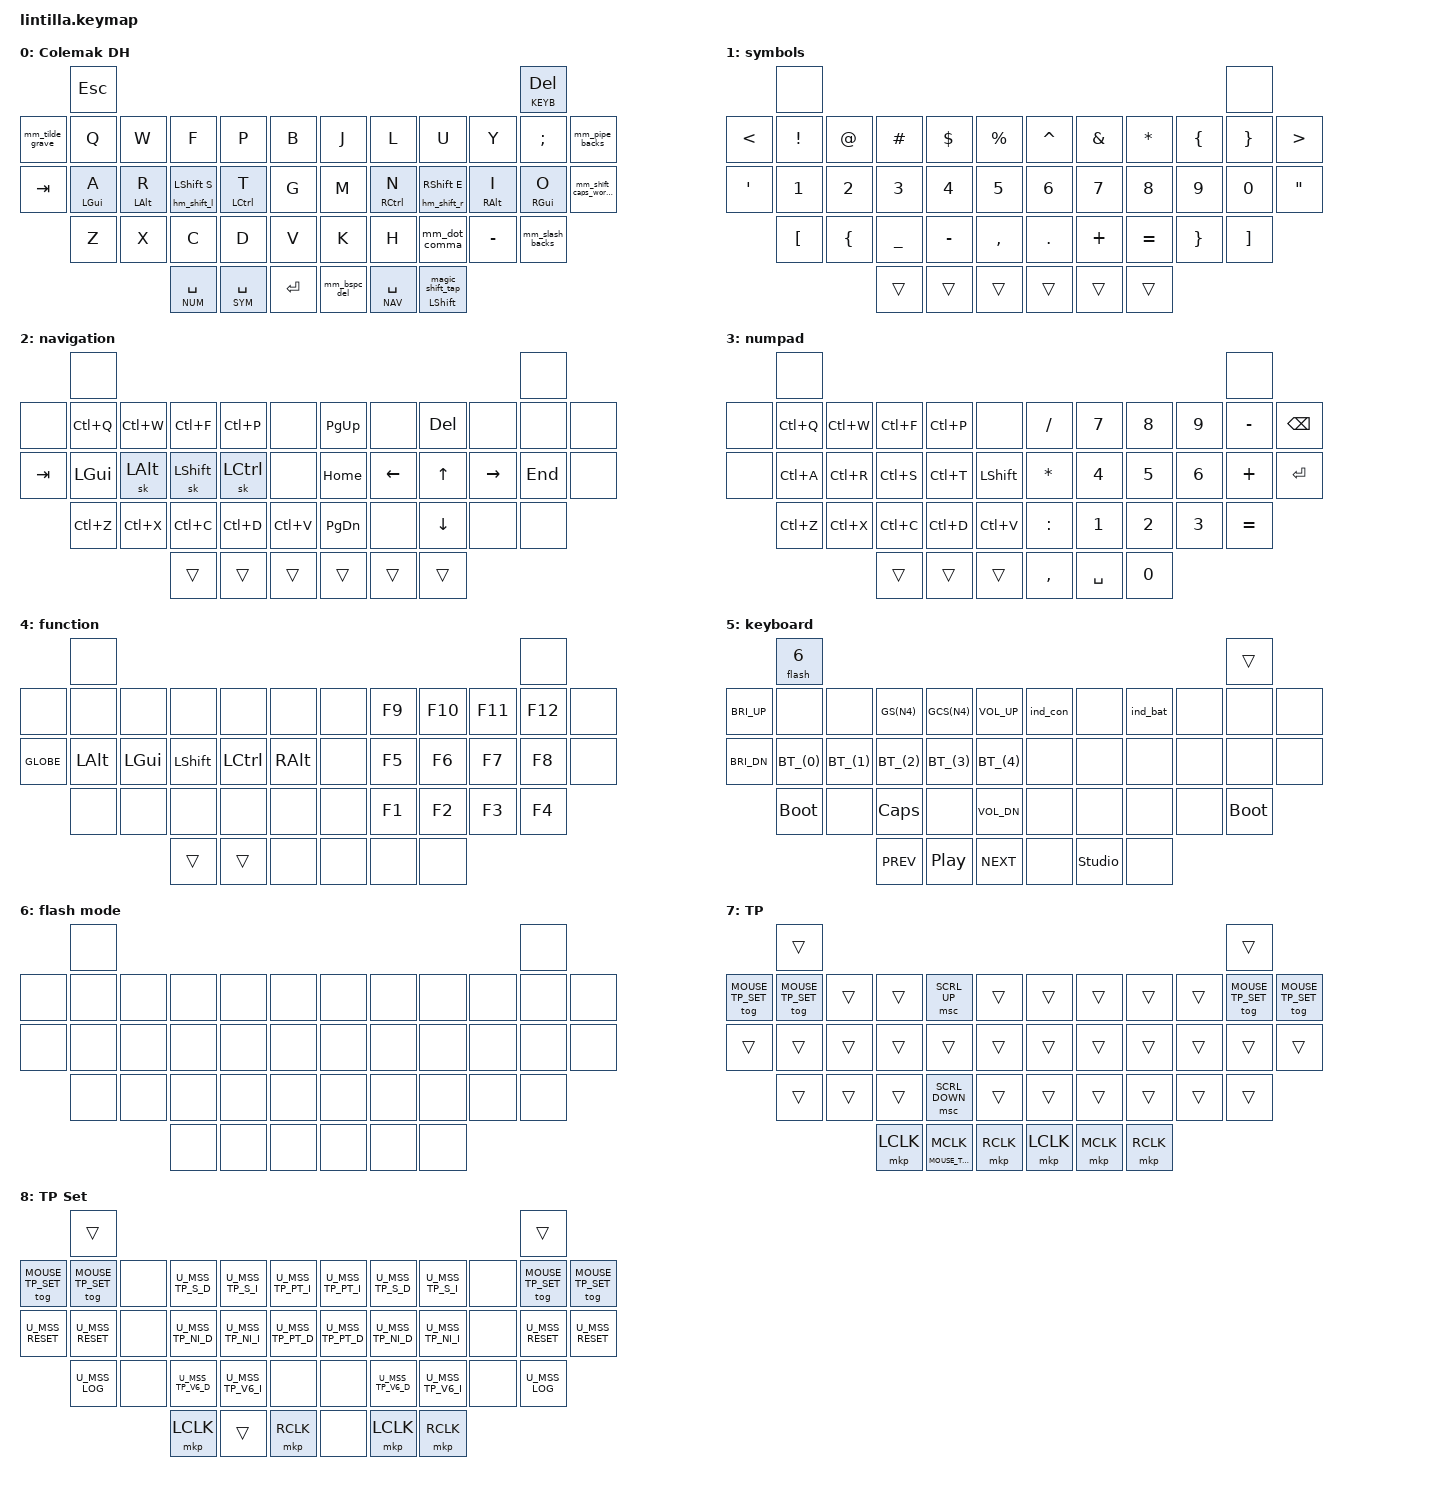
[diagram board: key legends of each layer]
#include "includes/lintilla.h"

#define KEYS_L LN0 LT0 LT1 LT2 LT3 LT4 LT5 LM0 LM1 LM2 LM3 LM4 LM5 LB0 LB1 LB2 LB3 LB4
#define KEYS_R RN0 RT0 RT1 RT2 RT3 RT4 RT5 RM0 RM1 RM2 RM3 RM4 RM5 RB0 RB1 RB2 RB3 RB4
#define KEYS_T LH2 LH1 LH0 RH0 RH1 RH2

#include <behaviors.dtsi>
#include <dt-bindings/zmk/bt.h>
#include <dt-bindings/zmk/keys.h>
#include <dt-bindings/zmk/outputs.h>
#include <dt-bindings/zmk/pointing.h>
#include <behaviors/rgbled_widget.dtsi>

// Personal includes
#define HOST_OS 1
#include "zmk-helpers/helper.h"

// Set the scroll amount
#undef ZMK_MOUSE_DEFAULT_SCRL_VAL
#define ZMK_MOUSE_DEFAULT_SCRL_VAL 1000

#undef SCRL_UP
#undef SCRL_DOWN
#undef SCRL_LEFT
#undef SCRL_RIGHT
#define SCRL_UP MOVE_Y(ZMK_MOUSE_DEFAULT_SCRL_VAL)
#define SCRL_DOWN MOVE_Y(-ZMK_MOUSE_DEFAULT_SCRL_VAL)
#define SCRL_LEFT MOVE_X(-ZMK_MOUSE_DEFAULT_SCRL_VAL)
#define SCRL_RIGHT MOVE_X(ZMK_MOUSE_DEFAULT_SCRL_VAL)
#define HAS_MOUSE_TP

// Source unicode-chars for desired languages
#include "zmk-helpers/unicode-chars/german.dtsi"
#include "includes/settings.dtsi"
#include "includes/behaviors_homerow_mods.dtsi"
#include "includes/behaviors_mod_morph.dtsi"
#include "includes/behaviors_other.dtsi"
#ifdef HAS_MOUSE_TP
  // We store the trackpoint settings in a separate file
  // to make organization a little easier.
  #include "includes/mouse_tp.dtsi"
#endif  // HAS_MOUSE_TP
#ifdef HAS_MOUSE_TP
  #define U_TOG_TP_SET &tog MOUSE_TP_SET
#else
  #define U_TOG_TP_SET &none
#endif  // HAS_MOUSE_TP

// Multiple mods
#define GS(key) &kp LG(LS(key))
#define GCS(key) &kp LG(LC(LS(key)))
#define HYPR(key) &kp LG(LA(LC(LS(key))))

// Shortcuts for home row mods
#define Glb &hm GLOBE
#define Sft &hm LSHFT
#define Ctl &hm LCTRL
#define Opt &hm LALT
#define Cmd &hm LGUI
#define Alt &hm RALT

// Magic bluetooth button
#define BT_(btnum) &bt_key btnum btnum

#define QUICK_TAP_MS 175

// Tap: repeat after alpha, else sticky-shift |
// Shift + tap/ double-tap: caps-word | Hold: shift.
#define MAGIC_SHIFT &magic_shift LSHFT 0
ZMK_HOLD_TAP(magic_shift, bindings = <&kp>, <&magic_shift_tap>;
             flavor = "balanced"; tapping-term-ms = <200>;
             quick-tap-ms = <QUICK_TAP_MS>;)
ZMK_MOD_MORPH(magic_shift_tap, bindings = <&sk LSHFT>, <&caps_word>;
              mods = <(MOD_LSFT)>;)

//&msc {
//    time-to-max-speed-ms = <1000>;
//};

/ {
    behaviors {
        bt_key: magic_bluetooth_key {
            compatible = "zmk,behavior-hold-tap";
            #binding-cells = <2>;
            flavor = "tap-preferred";
            tapping-term-ms = <500>;
            bindings = <&bt_clr>, <&bt_sel>;
        };

        hrm: homerow_mod {
            compatible = "zmk,behavior-hold-tap";
            #binding-cells = <2>;
            tapping-term-ms = <300>;
            require-prior-idle-ms = <150>;
            quick-tap-ms = <0>;
            flavor = "tap-preferred";
            bindings = <&kp>, <&kp>;
        };

        // Setting behavior for scrolling
        mouse_wheel: mouse_wheel {
            compatible = "zmk,behavior-sensor-rotate-var";
            label = "MOUSE_WHEEL";
            #sensor-binding-cells = <2>;
            bindings = <&msc>, <&msc>;
            tap-ms = <20>;
            };
    };

    conditional_layers {
        compatible = "zmk,conditional-layers";
        function_layer {
            if-layers = <NUM SYM>;
            then-layer = <FUNC>;
        };
    };

    macros {
        bt_clr: bluetooth_clear {
            compatible = "zmk,behavior-macro-one-param";
            #binding-cells = <1>;
            bindings = <&macro_param_1to1 &bt_sel MACRO_PLACEHOLDER>, <&bt BT_CLR>;
        };

        bt_sel: bluetooth_select {
            compatible = "zmk,behavior-macro-one-param";
            #binding-cells = <1>;
            bindings = <&out OUT_BLE>, <&macro_param_1to2 &bt BT_SEL MACRO_PLACEHOLDER>;
        };

        flash: dongle_bootloader {
            compatible = "zmk,behavior-macro-one-param";
            #binding-cells = <1>;
            bindings = <&macro_param_1to1 &to MACRO_PLACEHOLDER>, <&bootloader>;
        };
    };

    keymap {
        compatible = "zmk,keymap";

        colemak {
//                       ┏━━━━━━━━━━━━━━━━━━━━━━━━━┓
            display-name = "Colemak DH"                ;
//                       ┗━━━━━━━━━━━━━━━━━━━━━━━━━┛
            bindings = <
//                          ╭────────────────────────╮                                                                                                                                                                                                           ╭────────────────────────╮
                              &kp ESC                                                                                                                                                                                                                              &lt KEYB DEL                                                
// ╭────────────────────────┼────────────────────────┼────────────────────────┬────────────────────────┬────────────────────────┬────────────────────────╮    ╭────────────────────────┬────────────────────────┬────────────────────────┬───────────────────────┼────────────────────────┼────────────────────────╮
     &mm_tilde_grave          &kp Q                    &kp W                    &kp F                    &kp P                    &kp B                         &kp J                    &kp L                    &kp U                    &kp Y                   &kp SEMICOLON            &mm_pipe_backs
// ├────────────────────────┼────────────────────────┼────────────────────────┼────────────────────────┼────────────────────────┼────────────────────────┤    ├────────────────────────┼────────────────────────┼────────────────────────┼───────────────────────┼────────────────────────┼────────────────────────┤
     &kp TAB                  &hm_l LGUI A             &hm_l LALT R             &hm_shift_l LSHFT S      &hm_l LCTRL T            &kp G                         &kp M                    &hm_r RCTRL N            &hm_shift_r RSHFT E      &hm_r RALT I            &hm_r RGUI O             &mm_shift_caps_word_r
// ╰────────────────────────┼────────────────────────┼────────────────────────┼────────────────────────┼────────────────────────┼────────────────────────┤    ├────────────────────────┼────────────────────────┼────────────────────────┼───────────────────────┼────────────────────────┼────────────────────────╯
                              &kp Z                    &kp X                    &kp C                    &kp D                    &kp V                         &kp K                    &kp H                    &mm_dot_comma            &kp MINUS                &mm_slash_backs              
//                          ╰────────────────────────┴────────────────────────┴────────────────────────┼────────────────────────┼────────────────────────┤    ├────────────────────────┼────────────────────────┼────────────────────────┼───────────────────────┴────────────────────────╯
                                                                                &lt NUM SPACE           &lt SYM SPACE            &kp RETURN                     &mm_bspc_del             &lt NAV SPACE            MAGIC_SHIFT
//                                                                            ╰────────────────────────┴────────────────────────┴────────────────────────╯    ╰────────────────────────┴────────────────────────┴────────────────────────╯
      >;
    sensor-bindings = <&mouse_wheel SCRL_UP SCRL_DOWN>;
    };

//    Base_Qwerty_layer {
//      display-name = "QWERTY";
//      bindings = <
////                          ╭────────────────────────╮                                                                                                                                                                                                           ╭────────────────────────╮
//                              &trans                                                                                                                                                                                                                                &trans                                                
//// ╭────────────────────────┼────────────────────────┼────────────────────────┬────────────────────────┬────────────────────────┬────────────────────────╮    ╭────────────────────────┬────────────────────────┬────────────────────────┬───────────────────────┼────────────────────────┼────────────────────────╮
//     &trans                   &trans                   &trans                   &kp E                    &kp R                    &kp T                         &kp Y                    &kp U                    &kp I                    &kp O                    &kp P                     &trans
//// ├────────────────────────┼────────────────────────┼────────────────────────┼────────────────────────┼────────────────────────┼────────────────────────┤    ├────────────────────────┼────────────────────────┼────────────────────────┼───────────────────────┼────────────────────────┼────────────────────────┤
//     &trans                   &kp A                    &kp S                    &kp D                    &kp F                    &trans                        &kp H                    &kp J                    &kp K                    &kp L                    &kp SEMICOLON             &trans
//// ╰────────────────────────┼────────────────────────┼────────────────────────┼────────────────────────┼────────────────────────┼────────────────────────┤    ├────────────────────────┼────────────────────────┼────────────────────────┼───────────────────────┼────────────────────────┼────────────────────────╯
//                              &trans                   &trans                   &kp C                    &kp V                    &kp B                         &kp N                    &kp M                    &kp COMMA                &trans                   &trans                 
////                          ╰────────────────────────┴────────────────────────┴────────────────────────┼────────────────────────┼────────────────────────┤    ├────────────────────────┼────────────────────────┼────────────────────────┼───────────────────────┴────────────────────────╯
//                                                                                &trans                   &trans                   &trans                        &trans                   &trans                   &trans
////                                                                            ╰────────────────────────┴────────────────────────┴────────────────────────╯    ╰────────────────────────┴────────────────────────┴────────────────────────╯
//      >;
//    };

        sym {
//                       ┏━━━━━━━━━━━━━━━━━━━━━━━━━┓
            display-name = "symbols"               ;
//                       ┗━━━━━━━━━━━━━━━━━━━━━━━━━┛
            bindings = <
//         ┏━━━━━━━┓                                                                                          ┏━━━━━━━┓
//         ┃       ┃                                                                                          ┃       ┃
             &none                                                                                              &none
// ┏━━━━━━━╋━━━━━━━╋━━━━━━━┳━━━━━━━┳━━━━━━━┳━━━━━━━┓                          ┏━━━━━━━┳━━━━━━━┳━━━━━━━┳━━━━━━━╋━━━━━━━╋━━━━━━━┓
// ┃   <   ┃   !   ┃   @   ┃   #   ┃   $   ┃   %   ┃                          ┃    ^  ┃   &   ┃   *   ┃  (    ┃   )   ┃   >   ┃
    &kp LT &kp EXCL &kp AT  &kp HASH &kp DLLR &kp PRCNT                        &kp CARET &kp AMPS &kp STAR &kp LEFT_BRACE &kp RIGHT_BRACE &kp GT
// ┣━━━━━━━╋━━━━━━━╋━━━━━━━╋━━━━━━━╋━━━━━━━╋━━━━━━━┫                          ┣━━━━━━━╋━━━━━━━╋━━━━━━━╋━━━━━━━╋━━━━━━━╋━━━━━━━┫
// ┃   '   ┃   1   ┃   2   ┃   3   ┃   4   ┃   5   ┃                          ┃   6   ┃   7   ┃   8   ┃   9   ┃   0   ┃   "   ┃
    &kp SINGLE_QUOTE  &kp N1  &kp N2  &kp N3  &kp N4  &kp N5                   &kp N6  &kp N7  &kp N8  &kp N9  &kp N0  &kp DOUBLE_QUOTES
// ┗━━━━━━━╋━━━━━━━╋━━━━━━━╋━━━━━━━╋━━━━━━━╋━━━━━━━┫                          ┣━━━━━━━╋━━━━━━━╋━━━━━━━╋━━━━━━━╋━━━━━━━╋━━━━━━━┛
//         ┃   [   ┃   {   ┃   _   ┃   -   ┃   ,   ┃                          ┃   .   ┃   +   ┃   =   ┃   }   ┃   ]   ┃
            &kp LBKT &kp LBRC &kp UNDER &kp MINUS &kp COMMA                    &kp DOT &kp PLUS &kp EQUAL &kp RBRC &kp RBKT
//         ┗━━━━━━━┻━━━━━━━┻━━━━━━━┻━━━┳━━━┻━━━┳━━━┻━━━┳━━━━━━━┓  ┏━━━━━━━┳━━━┻━━━┳━━━┻━━━┳━━━┻━━━━━━━┻━━━━━━━┻━━━━━━━┛
//                                     ┃ ##### ┃ ##### ┃ ##### ┃  ┃ ##### ┃ ##### ┃ ##### ┃
                                         &trans  &trans  &trans    &trans  &trans  &trans
//                                     ┗━━━━━━━┫       ┣━━━━━━━┛  ┗━━━━━━━┫       ┣━━━━━━━┛
//                                             ┗━━━━━━━┛                  ┗━━━━━━━┛
            >;
        sensor-bindings = <&inc_dec_kp PLUS MINUS>;

        };

        nav {
//                       ┏━━━━━━━━━━━━━━━━━━━━━━━━━┓
            display-name = "navigation"            ;
//                       ┗━━━━━━━━━━━━━━━━━━━━━━━━━┛
            bindings = <
//         ┏━━━━━━━┓                                                                                          ┏━━━━━━━┓
//         ┃       ┃                                                                                          ┃       ┃
             &none                                                                                              &none
// ┏━━━━━━━╋━━━━━━━╋━━━━━━━┳━━━━━━━┳━━━━━━━┳━━━━━━━┓                          ┏━━━━━━━┳━━━━━━━┳━━━━━━━┳━━━━━━━╋━━━━━━━╋━━━━━━━┓
// ┃       ┃       ┃       ┃       ┃       ┃       ┃                          ┃ Pg Up ┃       ┃  DEL  ┃       ┃       ┃       ┃
&none &kp LC(Q) &kp LC(W) &kp LC(F) &kp LC(P) &none                           &kp PG_UP &none   &kp DEL &none   &none   &none
// ┣━━━━━━━╋━━━━━━━╋━━━━━━━╋━━━━━━━╋━━━━━━━╋━━━━━━━┫                          ┣━━━━━━━╋━━━━━━━╋━━━━━━━╋━━━━━━━╋━━━━━━━╋━━━━━━━┫
// ┃       ┃ LGUI  ┃  LALT ┃ LSHFT ┃ LCTRL ┃ none  ┃                          ┃ Home  ┃ Left  ┃  Up   ┃ Right ┃  End  ┃       ┃
&kp TAB &kp LGUI &sk LALT &sk LSHFT &sk LCTRL &none                           &kp HOME &kp LEFT &kp UP &kp RIGHT &kp END &none
// ┃       ┃       ┃       ┃       ┃       ┃       ┃                          ┃       ┃       ┃       ┃       ┃       ┃       ┃
// ┗━━━━━━━╋━━━━━━━╋━━━━━━━╋━━━━━━━╋━━━━━━━╋━━━━━━━┫                          ┣━━━━━━━╋━━━━━━━╋━━━━━━━╋━━━━━━━╋━━━━━━━╋━━━━━━━┛
//         ┃ CtrlZ ┃ CtrlX ┃ CtrlC ┃ CtrlD ┃ CtrlV ┃                          ┃ Pg Dn ┃       ┃ Down  ┃       ┃       ┃
         &kp LC(Z) &kp LC(X) &kp LC(C) &kp LC(D) &kp LC(V)                    &kp PG_DN &none  &kp DOWN &none   &none
//         ┗━━━━━━━┻━━━━━━━┻━━━━━━━┻━━━┳━━━┻━━━┳━━━┻━━━┳━━━━━━━┓  ┏━━━━━━━┳━━━┻━━━┳━━━┻━━━┳━━━┻━━━━━━━┻━━━━━━━┻━━━━━━━┛
//                                     ┃ ##### ┃ ##### ┃ ##### ┃  ┃ ##### ┃ ##### ┃ ##### ┃
                                         &trans  &trans  &trans     &trans  &trans  &trans
//                                     ┗━━━━━━━┫       ┣━━━━━━━┛  ┗━━━━━━━┫       ┣━━━━━━━┛
//                                             ┗━━━━━━━┛                  ┗━━━━━━━┛
            >;
     //sensor-bindings = <&mouse_wheel SCROLL_RIGHT SCROLL_LEFT>;
    sensor-bindings = <&inc_dec_kp C_VOL_UP C_VOL_DN>;
        };

        num {
//                       ┏━━━━━━━━━━━━━━━━━━━━━━━━━┓
            display-name = "numpad"                ;
//                       ┗━━━━━━━━━━━━━━━━━━━━━━━━━┛
            bindings = <
//         ┏━━━━━━━┓                                                                                          ┏━━━━━━━┓
//         ┃       ┃                                                                                          ┃       ┃
             &none                                                                                              &none
// ┏━━━━━━━╋━━━━━━━╋━━━━━━━┳━━━━━━━┳━━━━━━━┳━━━━━━━┓                          ┏━━━━━━━┳━━━━━━━┳━━━━━━━┳━━━━━━━╋━━━━━━━╋━━━━━━━┓
// ┃       ┃       ┃       ┃       ┃       ┃       ┃                          ┃   /   ┃   7   ┃   8   ┃   9   ┃   -   ┃ BKSPC ┃
&none &kp LC(Q) &kp LC(W) &kp LC(F) &kp LC(P) &none                           &kp SLASH &kp N7 &kp N8  &kp N9 &kp MINUS &kp BSPC
// ┣━━━━━━━╋━━━━━━━╋━━━━━━━╋━━━━━━━╋━━━━━━━╋━━━━━━━┫                          ┣━━━━━━━╋━━━━━━━╋━━━━━━━╋━━━━━━━╋━━━━━━━╋━━━━━━━┫
// ┃       ┃ CtrlA ┃ CtrlR ┃ CtrlS ┃ CtrlT ┃ LSHFT ┃                          ┃   *   ┃   4   ┃   5   ┃   6   ┃   +   ┃RETURN ┃
&none &kp LC(A) &kp LC(R) &kp LC(S) &kp LC(T) &kp LSHFT                       &kp STAR &kp N4  &kp N5  &kp N6 &kp PLUS &kp RET
// ┃       ┃       ┃       ┃       ┃       ┃       ┃                          ┃       ┃       ┃       ┃       ┃       ┃       ┃
// ┗━━━━━━━╋━━━━━━━╋━━━━━━━╋━━━━━━━╋━━━━━━━╋━━━━━━━┫                          ┣━━━━━━━╋━━━━━━━╋━━━━━━━╋━━━━━━━╋━━━━━━━╋━━━━━━━┛
//         ┃ CtrlZ ┃ CtrlX ┃ CtrlC ┃ CtrlD ┃ CtrlV ┃                          ┃   :   ┃   1   ┃   2   ┃   3   ┃   =   ┃
         &kp LC(Z) &kp LC(X) &kp LC(C) &kp LC(D) &kp LC(V)                    &kp COLON &kp N1 &kp N2  &kp N3 &kp EQUAL
//         ┗━━━━━━━┻━━━━━━━┻━━━━━━━┻━━━┳━━━┻━━━┳━━━┻━━━┳━━━━━━━┓  ┏━━━━━━━┳━━━┻━━━┳━━━┻━━━┳━━━┻━━━━━━━┻━━━━━━━┻━━━━━━━┛
//                                     ┃ ##### ┃ ##### ┃ ##### ┃  ┃   .   ┃ SPACE ┃   0   ┃
                                         &trans  &trans  &trans    &kp COMMA &kp SPC &kp N0
//                                     ┗━━━━━━━┫       ┣━━━━━━━┛  ┗━━━━━━━┫       ┣━━━━━━━┛
//                                             ┗━━━━━━━┛                  ┗━━━━━━━┛
            >;
        };

        fn {
//                       ┏━━━━━━━━━━━━━━━━━━━━━━━━━┓
            display-name = "function"              ;
//                       ┗━━━━━━━━━━━━━━━━━━━━━━━━━┛
            bindings = <
//         ┏━━━━━━━┓                                                                                          ┏━━━━━━━┓
//         ┃       ┃                                                                                          ┃       ┃
             &none                                                                                              &none
// ┏━━━━━━━╋━━━━━━━╋━━━━━━━┳━━━━━━━┳━━━━━━━┳━━━━━━━┓                          ┏━━━━━━━┳━━━━━━━┳━━━━━━━┳━━━━━━━╋━━━━━━━╋━━━━━━━┓
// ┃       ┃       ┃       ┃       ┃       ┃       ┃                          ┃       ┃  F9   ┃  F10  ┃  F11  ┃  F12  ┃       ┃
     &none   &none   &none   &none   &none   &none                              &none  &kp F9  &kp F10 &kp F11 &kp F12  &none
// ┣━━━━━━━╋━━━━━━━╋━━━━━━━╋━━━━━━━╋━━━━━━━╋━━━━━━━┫                          ┣━━━━━━━╋━━━━━━━╋━━━━━━━╋━━━━━━━╋━━━━━━━╋━━━━━━━┫
// ┃ Globe ┃ L Alt ┃  GUI  ┃ Shift ┃  Ctrl ┃ R Alt ┃                          ┃       ┃  F5   ┃  F6   ┃  F7   ┃  F8   ┃       ┃
&kp GLOBE  &kp LALT  &kp LGUI  &kp LSHFT &kp LCTL &kp RALT                      &none  &kp F5  &kp F6  &kp F7  &kp F8   &none
// ┗━━━━━━━╋━━━━━━━╋━━━━━━━╋━━━━━━━╋━━━━━━━╋━━━━━━━┫                          ┣━━━━━━━╋━━━━━━━╋━━━━━━━╋━━━━━━━╋━━━━━━━╋━━━━━━━┛
//         ┃       ┃       ┃       ┃       ┃       ┃                          ┃       ┃  F1   ┃  F2   ┃  F3   ┃  F4   ┃
             &none   &none   &none   &none   &none                              &none  &kp F1  &kp F2  &kp F3  &kp F4
//         ┗━━━━━━━┻━━━━━━━┻━━━━━━━┻━━━┳━━━┻━━━┳━━━┻━━━┳━━━━━━━┓  ┏━━━━━━━┳━━━┻━━━┳━━━┻━━━┳━━━┻━━━━━━━┻━━━━━━━┻━━━━━━━┛
//                                     ┃ ##### ┃ ##### ┃       ┃  ┃       ┃       ┃       ┃
                                         &trans  &trans  &none      &none   &none   &none
//                                     ┗━━━━━━━┫       ┣━━━━━━━┛  ┗━━━━━━━┫       ┣━━━━━━━┛
//                                             ┗━━━━━━━┛                  ┗━━━━━━━┛
            >;
        };

        keybd {
//                       ┏━━━━━━━━━━━━━━━━━━━━━━━━━┓
            display-name = "keyboard"              ;
//                       ┗━━━━━━━━━━━━━━━━━━━━━━━━━┛
            bindings = <
//         ┏━━━━━━━┓                                                                                          ┏━━━━━━━┓
//         ┃ dongle┃                                                                                          ┃ ##### ┃
           &flash 6                                                                                             &trans
// ┏━━━━━━━╋━━━━━━━╋━━━━━━━┳━━━━━━━┳━━━━━━━┳━━━━━━━┓                          ┏━━━━━━━┳━━━━━━━┳━━━━━━━┳━━━━━━━╋━━━━━━━╋━━━━━━━┓
// ┃ brt + ┃       ┃       ┃scrnsht┃scrn cp┃ vol + ┃                          ┃con led┃       ┃bat led┃       ┃       ┃       ┃
&kp C_BRI_UP &none   &none  GS(N4) GCS(N4) &kp C_VOL_UP                       &ind_con  &none &ind_bat  &none   &none   &none
// ┣━━━━━━━╋━━━━━━━╋━━━━━━━╋━━━━━━━╋━━━━━━━╋━━━━━━━┫                          ┣━━━━━━━╋━━━━━━━╋━━━━━━━╋━━━━━━━╋━━━━━━━╋━━━━━━━┫
// ┃ brt - ┃  BT1  ┃  BT2  ┃  BT3  ┃  BT4  ┃  BT5  ┃                          ┃       ┃       ┃       ┃       ┃       ┃       ┃
&kp C_BRI_DN BT_(0)  BT_(1)  BT_(2)  BT_(3)  BT_(4)                             &none   &none   &none   &none   &none   &none
// ┗━━━━━━━╋━━━━━━━╋━━━━━━━╋━━━━━━━╋━━━━━━━╋━━━━━━━┫                          ┣━━━━━━━╋━━━━━━━╋━━━━━━━╋━━━━━━━╋━━━━━━━╋━━━━━━━┛
//         ┃ flash ┃       ┃caps lk┃       ┃ vol - ┃                          ┃       ┃       ┃       ┃       ┃ flash ┃
        &bootloader &none &kp CAPS &none &kp C_VOL_DN                           &none   &none   &none   &none &bootloader
//         ┗━━━━━━━┻━━━━━━━┻━━━━━━━┻━━━┳━━━┻━━━┳━━━┻━━━┳━━━━━━━┓  ┏━━━━━━━┳━━━┻━━━┳━━━┻━━━┳━━━┻━━━━━━━┻━━━━━━━┻━━━━━━━┛
//                                     ┃ prev  ┃ play  ┃ next  ┃  ┃       ┃studio ┃       ┃
                                   &kp C_PREV &kp C_PP &kp C_NEXT &none &studio_unlock &none
//                                     ┗━━━━━━━┫       ┣━━━━━━━┛  ┗━━━━━━━┫ unlock┣━━━━━━━┛
//                                             ┗━━━━━━━┛                  ┗━━━━━━━┛
            >;
        };

        flash {
//                       ┏━━━━━━━━━━━━━━━━━━━━━━━━━┓
            display-name = "flash mode"            ;
//                       ┗━━━━━━━━━━━━━━━━━━━━━━━━━┛
            bindings = <
//         ┏━━━━━━━┓                                                                                          ┏━━━━━━━┓
//         ┃       ┃                                                                                          ┃       ┃
             &none                                                                                              &none
// ┏━━━━━━━╋━━━━━━━╋━━━━━━━┳━━━━━━━┳━━━━━━━┳━━━━━━━┓                          ┏━━━━━━━┳━━━━━━━┳━━━━━━━┳━━━━━━━╋━━━━━━━╋━━━━━━━┓
// ┃       ┃       ┃       ┃       ┃       ┃       ┃                          ┃       ┃       ┃       ┃       ┃       ┃       ┃
     &none   &none   &none   &none   &none   &none                              &none   &none   &none   &none   &none   &none
// ┣━━━━━━━╋━━━━━━━╋━━━━━━━╋━━━━━━━╋━━━━━━━╋━━━━━━━┫                          ┣━━━━━━━╋━━━━━━━╋━━━━━━━╋━━━━━━━╋━━━━━━━╋━━━━━━━┫
// ┃       ┃       ┃       ┃       ┃       ┃       ┃                          ┃       ┃       ┃       ┃       ┃       ┃       ┃
     &none   &none   &none   &none   &none   &none                              &none   &none   &none   &none   &none   &none
// ┗━━━━━━━╋━━━━━━━╋━━━━━━━╋━━━━━━━╋━━━━━━━╋━━━━━━━┫                          ┣━━━━━━━╋━━━━━━━╋━━━━━━━╋━━━━━━━╋━━━━━━━╋━━━━━━━┛
//         ┃       ┃       ┃       ┃       ┃       ┃                          ┃       ┃       ┃       ┃       ┃       ┃
             &none   &none   &none   &none   &none                              &none   &none   &none   &none   &none
//         ┗━━━━━━━┻━━━━━━━┻━━━━━━━┻━━━┳━━━┻━━━┳━━━┻━━━┳━━━━━━━┓  ┏━━━━━━━┳━━━┻━━━┳━━━┻━━━┳━━━┻━━━━━━━┻━━━━━━━┻━━━━━━━┛
//                                     ┃       ┃       ┃       ┃  ┃       ┃       ┃       ┃
                                         &none   &none   &none      &none   &none   &none
//                                     ┗━━━━━━━┫       ┣━━━━━━━┛  ┗━━━━━━━┫       ┣━━━━━━━┛
//                                             ┗━━━━━━━┛                  ┗━━━━━━━┛
            >;
        };
#ifdef HAS_MOUSE_TP

        // Automatically activated when the mouse or trackpoint moves.
        // Configured in `include/mouse_tp.dtsi`.
        MouseTP_layer {
        display-name = "TP";
        bindings = <

//                              ╭────────────────────────╮                                                                                                                                                                                                            ╭────────────────────────╮
                                 &trans                                                                                                                                                                                                                               &trans                                            
//     ╭────────────────────────┼────────────────────────┼────────────────────────┬────────────────────────┬────────────────────────┬────────────────────────╮    ╭────────────────────────┬────────────────────────┬────────────────────────┬────────────────────────┼────────────────────────┼────────────────────────╮
        U_TOG_TP_SET             U_TOG_TP_SET             &trans                   &trans                   &msc SCRL_UP             &trans                        &trans                   &trans                   &trans                   &trans                   U_TOG_TP_SET              U_TOG_TP_SET
    // ├────────────────────────┼────────────────────────┼────────────────────────┼────────────────────────┼────────────────────────┼────────────────────────┤    ├────────────────────────┼────────────────────────┼────────────────────────┼────────────────────────┼────────────────────────┼────────────────────────┤
        &trans                   &trans                   &trans                   &trans                   &trans                   &trans                        &trans                   &trans                   &trans                   &trans                   &trans                    &trans
    // ╰────────────────────────┼────────────────────────┼────────────────────────┼────────────────────────┼────────────────────────┼────────────────────────┤    ├────────────────────────┼────────────────────────┼────────────────────────┼────────────────────────┼────────────────────────┼────────────────────────╯
                                 &trans                   &trans                   &trans                   &msc SCRL_DOWN           &trans                        &trans                   &trans                   &trans                   &trans                   &trans                  
    //                          ╰────────────────────────┴────────────────────────┴────────────────────────┼────────────────────────┼────────────────────────┤    ├────────────────────────┼────────────────────────┼────────────────────────┼────────────────────────┴────────────────────────╯
                                                                                    &mkp LCLK               &lt_mkp MOUSE_TP_SET MCLK &mkp RCLK                     &mkp LCLK                &mkp MCLK                &mkp RCLK
    //                                                                            ╰────────────────────────┴────────────────────────┴────────────────────────╯    ╰────────────────────────┴────────────────────────┴────────────────────────╯
        >;
        };

        // You can find the defines for the actual key press behaviors in `include/mouse_tp.dtsi`.
        MouseSettings_layer {
        display-name = "TP Set";
        bindings = <
//                              ╭────────────────────────╮                                                                                                                                                                                                            ╭────────────────────────╮
                                 &trans                                                                                                                                                                                                                               &trans                                            
//     ╭────────────────────────┼────────────────────────┼────────────────────────┬────────────────────────┬────────────────────────┬────────────────────────╮    ╭────────────────────────┬────────────────────────┬────────────────────────┬────────────────────────┼────────────────────────┼────────────────────────╮
        U_TOG_TP_SET             U_TOG_TP_SET             &none                    U_MSS_TP_S_D             U_MSS_TP_S_I             U_MSS_TP_PT_I                 U_MSS_TP_PT_I            U_MSS_TP_S_D             U_MSS_TP_S_I             &none                    U_TOG_TP_SET              U_TOG_TP_SET
    // ├────────────────────────┼────────────────────────┼────────────────────────┼────────────────────────┼────────────────────────┼────────────────────────┤    ├────────────────────────┼────────────────────────┼────────────────────────┼────────────────────────┼────────────────────────┼────────────────────────┤
        U_MSS_RESET              U_MSS_RESET              &none                    U_MSS_TP_NI_D            U_MSS_TP_NI_I            U_MSS_TP_PT_D                 U_MSS_TP_PT_D            U_MSS_TP_NI_D            U_MSS_TP_NI_I            &none                    U_MSS_RESET               U_MSS_RESET
    // ╰────────────────────────┼────────────────────────┼────────────────────────┼────────────────────────┼────────────────────────┼────────────────────────┤    ├────────────────────────┼────────────────────────┼────────────────────────┼────────────────────────┼────────────────────────┼────────────────────────╯
                                 U_MSS_LOG                &none                    U_MSS_TP_V6_D            U_MSS_TP_V6_I            &none                         &none                    U_MSS_TP_V6_D            U_MSS_TP_V6_I            &none                    U_MSS_LOG               
    //                          ╰────────────────────────┴────────────────────────┴────────────────────────┼────────────────────────┼────────────────────────┤    ├────────────────────────┼────────────────────────┼────────────────────────┼────────────────────────┴────────────────────────╯
                                                                                    &mkp LCLK                &trans                   &mkp RCLK                     &none                    &mkp LCLK                &mkp RCLK
    //                                                                            ╰────────────────────────┴────────────────────────┴────────────────────────╯    ╰────────────────────────┴────────────────────────┴────────────────────────╯
        >;
        };
#endif
        // Extra empty layers for ZMK Studio

        layer10 {
            status = "reserved";
        };

        layer11 {
            status = "reserved";
        };

        layer12 {
            status = "reserved";
        };

        layer13 {
            status = "reserved";
        };

        layer14 {
            status = "reserved";
        };

        layer15 {
            status = "reserved";
        };
    };
};

// vim: expandtab softtabstop=4 shiftwidth=4 filetype=dts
